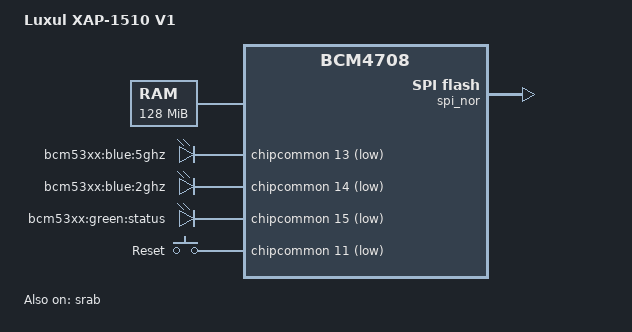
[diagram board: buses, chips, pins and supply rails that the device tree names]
// SPDX-License-Identifier: GPL-2.0-or-later OR MIT
/*
 * Copyright 2016 Luxul Inc.
 */

/dts-v1/;

#include "bcm4708.dtsi"

/ {
	compatible = "luxul,xap-1510v1", "brcm,bcm4708";
	model = "Luxul XAP-1510 V1";

	chosen {
		bootargs = "console=ttyS0,115200 earlycon";
	};

	memory@0 {
		device_type = "memory";
		reg = <0x00000000 0x08000000>;
	};

	leds {
		compatible = "gpio-leds";

		5ghz {
			label = "bcm53xx:blue:5ghz";
			gpios = <&chipcommon 13 GPIO_ACTIVE_LOW>;
			linux,default-trigger = "none";
		};

		2ghz {
			label = "bcm53xx:blue:2ghz";
			gpios = <&chipcommon 14 GPIO_ACTIVE_LOW>;
			linux,default-trigger = "none";
		};

		status {
			label = "bcm53xx:green:status";
			gpios = <&chipcommon 15 GPIO_ACTIVE_LOW>;
			linux,default-trigger = "timer";
		};
	};

	gpio-keys {
		compatible = "gpio-keys";

		restart {
			label = "Reset";
			linux,code = <KEY_RESTART>;
			gpios = <&chipcommon 11 GPIO_ACTIVE_LOW>;
		};
	};
};

&spi_nor {
	status = "okay";
};

&srab {
	status = "okay";

	ports {
		port@0 {
			reg = <0>;
			label = "poe";
		};

		port@4 {
			reg = <4>;
			label = "lan";
		};

		port@5 {
			reg = <5>;
			label = "cpu";
			ethernet = <&gmac0>;
		};
	};
};
